# RZT2L register map
Vendor: Renesas Electronics Corporation; Series: RZT; File version: 1.20.00
CPU: other r0p0, little endian, MPU, no FPU, VTOR, 4 interrupt priority bits, 624 interrupts
Registers are 32-bit, read-write, reset 0x0 unless marked. A register's access mark holds for its fields unless they carry their own. Offsets are from the block's base; [hi:lo] are bit positions; {n}, {i} and the like mark numbered series; 'fields as' and 'values as' point back to an identical list.

## MPU1 — Master MPU 1
Base 0x81281200
Same registers: MPU2 0x81281300, MPU6 0x81281700
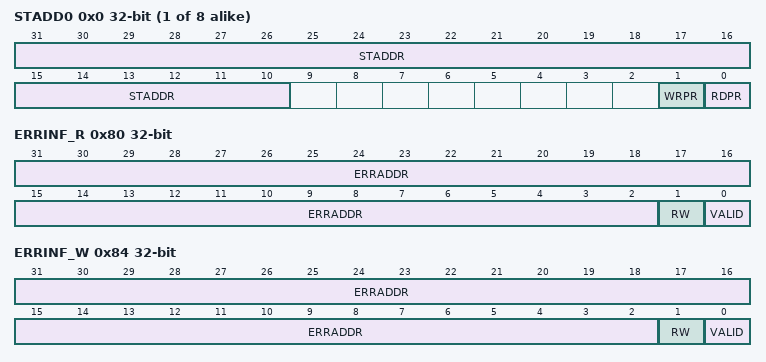
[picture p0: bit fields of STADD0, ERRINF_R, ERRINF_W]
{0x0+0x10*i} STADD{i} (i=0..7) (reset mask 0xFFFFFFFC) — Master MPU Safety Region Start Address Register {i}
  [31:10] STADDR — Start address for MPU region
  [1] WRPR — Enable write protection for region m of master MPU
    0=Disable write protection. Write access to the safety region is permitted.; 1=Enable write protection. Write access to the safety region is protected and error is generated.
  [0] RDPR — Enable read protection for region m of master MPU
    0=Disable read protection. Read access to the safety region is permitted.; 1=Enable read protection. Read access to the safety region is protected and error is generated.
{0x4+0x10*i} ENDADD{i} (i=0..7) (reset mask 0x3FF) — Master MPU Safety Region End Address Register {i}
  [31:10] ENDADDR — End address for MPU region
0x80 ERRINF_R — Master MPU Error Information Register for AXI type
  [31:2] ERRADDR ro — Access error address
  [1] RW ro — Access error type
    0=Read access; 1=Write access
  [0] VALID — Validity of access error information
    0=Error information is invalid; 1=Error information is valid
0x84 ERRINF_W — Master MPU Error Information Register for AXI type
  fields as ERRINF_R

## MPU3 — Master MPU 3
Base 0x81281400
Same registers: MPU4 0x81281500
Registers as MPU1, without ERRINF_R, ERRINF_W; these are added or differ:
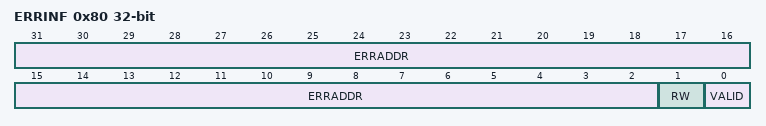
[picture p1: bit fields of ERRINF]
0x80 ERRINF — Master MPU Error Information Register for AHB type
  [31:2] ERRADDR ro — Access Error Address
  [1] RW ro — Access error type
    0=Read access; 1=Write access
  [0] VALID — Validity of Access Error Information
    0=Error information is invalid; 1=Error information is valid

## SYSRAM_CTL — System SRAM Control
Base 0x81281800
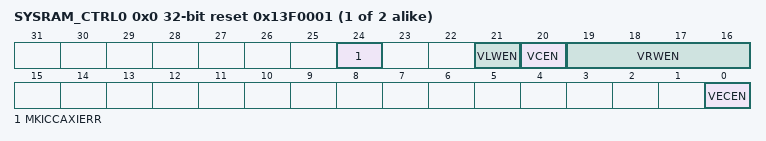
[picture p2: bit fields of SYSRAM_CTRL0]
{0x0+0x10*i} SYSRAM_CTRL{i} (i=0..1) reset 0x13F0001 — System SRAM Control Register {i}
  [24] MKICCAXIERR — Controls AXI-SLVERR issuance for ECC 2-bit errors
    0=Issue AXI-SLEVER; 1=Do not issue AXI-SLEVER
  [21] VLWEN — Enables write for RAM
    0=Disabled; 1=Enabled
  [20] VCEN — Enables access to RAM
    0=Disabled; 1=Enabled
  [19:16] VRWEN — Enables write for each page of RAM
    0=Disabled; 1=Enabled
  [0] VECEN — Enables or disables error correction with ECC
    0=Disabled; 1=Enabled

## TCMAW — TCM access wait state
Base 0x81281900
0x10 CPU0WAIT ro (reset mask 0xFFFFFFFE) — ATCM CPU0 Wait State Register
  [0] CPU0WAIT — ATCM CPU0 Wait state
    0=0-wait state (MDW = 0); 1=1-wait state (MDW = 1)

## SHOSTIF_CFG — Serial Host Interface Configuration
Base 0x81281920
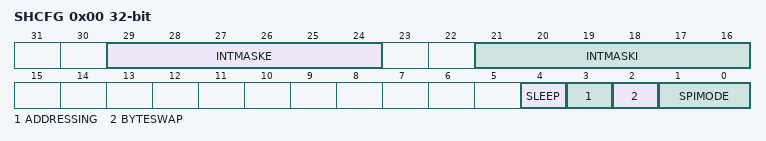
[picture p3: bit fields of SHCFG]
0x00 SHCFG — SHOSTIF Configuration Register
  [29:24] INTMASKE — Interrupt Mask Enable for External Interrupt (HSPI_INT# signal)
    0=No masked; 1=Masked
  [21:16] INTMASKI — Interrupt Mask Enable for Internal Interrupt (SHOST_INT)
    0=No masked; 1=Masked
  [4] SLEEP ro — SHOSTIF Enable Flag Monitor
    0=Not safe to stop the internal clock; 1=Safe to stop the internal clock
  [3] ADDRESSING — Addressing Mode
    0=32-bit; 1=8-bit
  [2] BYTESWAP — Byte Swap Mode
    0=No byte swap. Use this setting if byte order of data input by SPI master is [31:24], [23:16], [15:8], or [7:0].; 1=Byte swap. Use this setting if byte order of data input by SPI master is [7:0], [15:8], [23:16], or [31:24].
  [1:0] SPIMODE — SPI Frame Format Select
    0=Standard SPI mode; 1=SPI Dual mode; 2=SPI Quad mode; 3=SPI Octal mode

## RWP_S — Register Write Protection for Safety Area
Base 0x81281A00
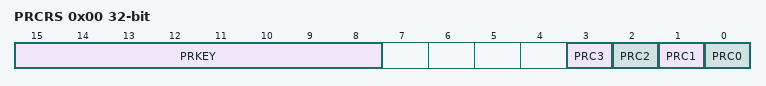
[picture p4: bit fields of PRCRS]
0x00 PRCRS — Safety Area Protect Register
  [15:8] PRKEY wo — PRC Key Code
  [n] PRC{n} (n=0..3) — Protect {n}
    0=Write disabled; 1=Write enabled
